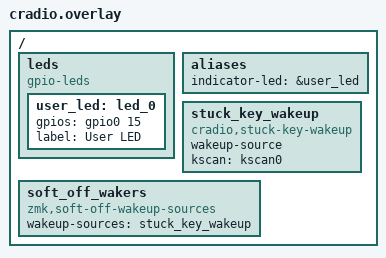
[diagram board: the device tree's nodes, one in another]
/ {
    leds {
        compatible = "gpio-leds";

        user_led: led_0 {
            gpios = <&gpio0 15 GPIO_ACTIVE_HIGH>;
            label = "User LED";
        };
    };

    aliases {
        indicator-led = &user_led;
    };

    stuck_key_wakeup: stuck_key_wakeup {
        compatible = "cradio,stuck-key-wakeup";
        status = "okay";
        wakeup-source;
        kscan = <&kscan0>;
    };

    soft_off_wakers {
        compatible = "zmk,soft-off-wakeup-sources";
        status = "okay";
        wakeup-sources = <&stuck_key_wakeup>;
    };
};
